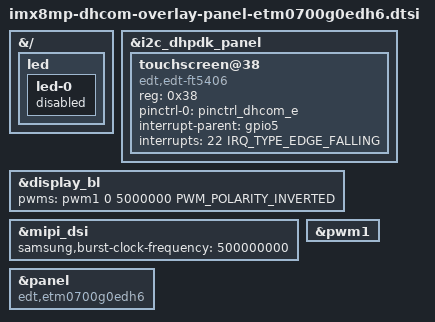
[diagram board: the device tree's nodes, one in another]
// SPDX-License-Identifier: (GPL-2.0+ OR BSD-3-Clause)
/*
 * Copyright (C) 2022-2026 Marek Vasut
 */
/dts-v1/;
/plugin/;

#include <dt-bindings/clock/imx8mp-clock.h>
#include "imx8mp-dhcom-overlay-panel-dpi.dtsi"

&{/} {
	led {
		led-0 {
			/* LED5 GPIO conflicts with Touchscreen IRQ GPIO-E */
			status = "disabled";
		};
	};
};

&i2c_dhpdk_panel {
	#address-cells = <1>;
	#size-cells = <0>;

	touchscreen@38 {
		compatible = "edt,edt-ft5406";
		reg = <0x38>;
		pinctrl-names = "default";
		pinctrl-0 = <&pinctrl_dhcom_e>;
		/* Touchscreen IRQ GPIO-E conflicts with LED5 GPIO */
		interrupt-parent = <&gpio5>;
		interrupts = <22 IRQ_TYPE_EDGE_FALLING>; /* GPIO E */
	};
};

&display_bl {
	pwms = <&pwm1 0 5000000 PWM_POLARITY_INVERTED>;
};

&mipi_dsi {
	/*
	 * This is DSIM PLL frequency, DSI HS clock lane frequency
	 * is half of the "samsung,burst-clock-frequency" value.
	 */
	samsung,burst-clock-frequency = <500000000>;
};

&panel {
	compatible = "edt,etm0700g0edh6";
};

&pwm1 {
	status = "okay";
};
